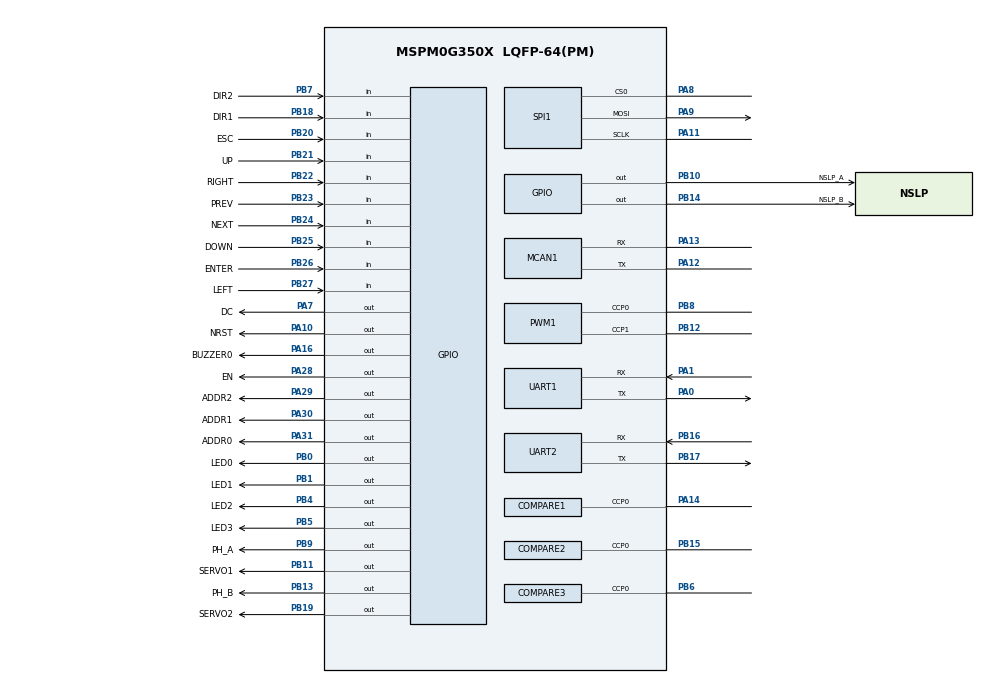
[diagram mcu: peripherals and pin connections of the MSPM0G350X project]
/**
 * @cliArgs --device "MSPM0G350X" --part "Default" --package "LQFP-64(PM)" --product "mspm0_sdk@2.05.01.00"
 * @versions {"tool":"1.24.1+4189"}
 */

/**
 * Import the modules used in this configuration.
 */
const ADC12         = scripting.addModule("/ti/driverlib/ADC12", {}, false);
const ADC121        = ADC12.addInstance();
const COMPARE       = scripting.addModule("/ti/driverlib/COMPARE", {}, false);
const COMPARE1      = COMPARE.addInstance();
const COMPARE2      = COMPARE.addInstance();
const COMPARE3      = COMPARE.addInstance();
const GPIO          = scripting.addModule("/ti/driverlib/GPIO", {}, false);
const GPIO1         = GPIO.addInstance();
const GPIO2         = GPIO.addInstance();
const GPIO3         = GPIO.addInstance();
const GPIO4         = GPIO.addInstance();
const GPIO5         = GPIO.addInstance();
const GPIO6         = GPIO.addInstance();
const GPIO7         = GPIO.addInstance();
const GPIO8         = GPIO.addInstance();
const GPIO9         = GPIO.addInstance();
const MATHACL       = scripting.addModule("/ti/driverlib/MATHACL");
const MCAN          = scripting.addModule("/ti/driverlib/MCAN", {}, false);
const MCAN1         = MCAN.addInstance();
const PWM           = scripting.addModule("/ti/driverlib/PWM", {}, false);
const PWM1          = PWM.addInstance();
const SPI           = scripting.addModule("/ti/driverlib/SPI", {}, false);
const SPI1          = SPI.addInstance();
const SYSCTL        = scripting.addModule("/ti/driverlib/SYSCTL");
const SYSTICK       = scripting.addModule("/ti/driverlib/SYSTICK");
const TIMER         = scripting.addModule("/ti/driverlib/TIMER", {}, false);
const TIMER1        = TIMER.addInstance();
const TIMER2        = TIMER.addInstance();
const UART          = scripting.addModule("/ti/driverlib/UART", {}, false);
const UART1         = UART.addInstance();
const UART2         = UART.addInstance();
const VREF          = scripting.addModule("/ti/driverlib/VREF");
const ProjectConfig = scripting.addModule("/ti/project_config/ProjectConfig");

/**
 * Write custom configuration values to the imported modules.
 */
const divider5       = system.clockTree["PLL_CLK1_DIV"];
divider5.divideValue = 4;

const divider6       = system.clockTree["PLL_CLK2X_DIV"];
divider6.divideValue = 4;

const divider7       = system.clockTree["PLL_PDIV"];
divider7.divideValue = 2;

const divider9       = system.clockTree["UDIV"];
divider9.divideValue = 2;

const gate7  = system.clockTree["MFCLKGATE"];
gate7.enable = true;

const gate8  = system.clockTree["MFPCLKGATE"];
gate8.enable = true;

const multiplier2         = system.clockTree["PLL_QDIV"];
multiplier2.multiplyValue = 10;

const mux2       = system.clockTree["CANCLKMUX"];
mux2.inputSelect = "CANCLKMUX_PLLCLK1_OUT";

const mux8       = system.clockTree["HSCLKMUX"];
mux8.inputSelect = "HSCLKMUX_SYSPLL2X";

ADC121.$name                 = "ADC12_0";
ADC121.samplingOperationMode = "sequence";
ADC121.adcMem0vref           = "VREF";
ADC121.sampClkSrc            = "DL_ADC12_CLOCK_ULPCLK";
ADC121.adcMem1chansel        = "DL_ADC12_INPUT_CHAN_1";
ADC121.adcMem1vref           = "VREF";
ADC121.adcMem2chansel        = "DL_ADC12_INPUT_CHAN_2";
ADC121.adcMem2vref           = "VREF";
ADC121.adcMem3chansel        = "DL_ADC12_INPUT_CHAN_3";
ADC121.adcMem3vref           = "VREF";
ADC121.adcMem4vref           = "VREF";
ADC121.sampleTime1           = "10us";
ADC121.enabledDMATriggers    = ["DL_ADC12_DMA_MEM11_RESULT_LOADED","DL_ADC12_DMA_MEM5_RESULT_LOADED"];
ADC121.enableDMA             = false;
ADC121.repeatMode            = true;
ADC121.endAdd                = 6;
ADC121.adcMem4chansel        = "DL_ADC12_INPUT_CHAN_7";
ADC121.adcMem5chansel        = "DL_ADC12_INPUT_CHAN_11";
ADC121.adcMem6chansel        = "DL_ADC12_INPUT_CHAN_15";
ADC121.adcMem6vref           = "VREF";
ADC121.enabledInterrupts     = ["DL_ADC12_INTERRUPT_MEM6_RESULT_LOADED"];
ADC121.adcMem5vref           = "VREF";
ADC121.sampleTime0           = "2us";
ADC121.adcMem0stime          = "DL_ADC12_SAMPLE_TIMER_SOURCE_SCOMP1";
ADC121.adcMem1stime          = "DL_ADC12_SAMPLE_TIMER_SOURCE_SCOMP1";
ADC121.adcMem2stime          = "DL_ADC12_SAMPLE_TIMER_SOURCE_SCOMP1";
ADC121.adcMem3stime          = "DL_ADC12_SAMPLE_TIMER_SOURCE_SCOMP1";
ADC121.adcMem4stime          = "DL_ADC12_SAMPLE_TIMER_SOURCE_SCOMP1";
ADC121.adcMem5stime          = "DL_ADC12_SAMPLE_TIMER_SOURCE_SCOMP1";
ADC121.adcMem6stime          = "DL_ADC12_SAMPLE_TIMER_SOURCE_SCOMP1";
ADC121.adcPin0Config.$name   = "ti_driverlib_gpio_GPIOPinGeneric11";
ADC121.adcPin1Config.$name   = "ti_driverlib_gpio_GPIOPinGeneric12";
ADC121.adcPin2Config.$name   = "ti_driverlib_gpio_GPIOPinGeneric13";
ADC121.adcPin3Config.$name   = "ti_driverlib_gpio_GPIOPinGeneric14";
ADC121.adcPin7Config.$name   = "ti_driverlib_gpio_GPIOPinGeneric19";

const Board = scripting.addModule("/ti/driverlib/Board", {}, false);

COMPARE1.$name                      = "COMPARE_0";
COMPARE1.timerPeriod                = 65535;
COMPARE1.peripheral.$assign         = "TIMG12";
COMPARE1.peripheral.ccp0Pin.$assign = "PA14";
COMPARE1.ccp0PinConfig.$name        = "CC";

COMPARE2.$name                      = "COMPARE_1";
COMPARE2.timerPeriod                = 65535;
COMPARE2.peripheral.$assign         = "TIMG7";
COMPARE2.peripheral.ccp0Pin.$assign = "PB15";
COMPARE2.ccp0PinConfig.$name        = "ti_driverlib_gpio_GPIOPinGeneric5";

COMPARE3.$name                      = "COMPARE_2";
COMPARE3.timerPeriod                = 65535;
COMPARE3.peripheral.$assign         = "TIMG6";
COMPARE3.peripheral.ccp0Pin.$assign = "PB6";
COMPARE3.ccp0PinConfig.$name        = "ti_driverlib_gpio_GPIOPinGeneric6";

GPIO1.$name                          = "LED";
GPIO1.associatedPins.create(4);
GPIO1.associatedPins[0].$name        = "LED0";
GPIO1.associatedPins[0].assignedPort = "PORTB";
GPIO1.associatedPins[0].assignedPin  = "0";
GPIO1.associatedPins[0].initialValue = "SET";
GPIO1.associatedPins[0].pin.$assign  = "PB0";
GPIO1.associatedPins[1].assignedPort = "PORTB";
GPIO1.associatedPins[1].assignedPin  = "1";
GPIO1.associatedPins[1].$name        = "LED1";
GPIO1.associatedPins[1].initialValue = "SET";
GPIO1.associatedPins[1].pin.$assign  = "PB1";
GPIO1.associatedPins[2].$name        = "LED2";
GPIO1.associatedPins[2].assignedPort = "PORTB";
GPIO1.associatedPins[2].assignedPin  = "4";
GPIO1.associatedPins[2].initialValue = "SET";
GPIO1.associatedPins[2].pin.$assign  = "PB4";
GPIO1.associatedPins[3].$name        = "LED3";
GPIO1.associatedPins[3].assignedPort = "PORTB";
GPIO1.associatedPins[3].assignedPin  = "5";
GPIO1.associatedPins[3].initialValue = "SET";
GPIO1.associatedPins[3].pin.$assign  = "PB5";

GPIO2.$name                          = "BUZZER";
GPIO2.associatedPins[0].$name        = "BUZZER0";
GPIO2.associatedPins[0].initialValue = "SET";
GPIO2.associatedPins[0].assignedPort = "PORTA";
GPIO2.associatedPins[0].assignedPin  = "16";
GPIO2.associatedPins[0].pin.$assign  = "PA16";

GPIO3.$name                         = "BUTTON";
GPIO3.port                          = "PORTB";
GPIO3.associatedPins.create(8);
GPIO3.associatedPins[0].$name       = "UP";
GPIO3.associatedPins[0].assignedPin = "21";
GPIO3.associatedPins[0].direction   = "INPUT";
GPIO3.associatedPins[0].pin.$assign = "PB21";
GPIO3.associatedPins[1].$name       = "DOWN";
GPIO3.associatedPins[1].assignedPin = "25";
GPIO3.associatedPins[1].direction   = "INPUT";
GPIO3.associatedPins[1].pin.$assign = "PB25";
GPIO3.associatedPins[2].$name       = "LEFT";
GPIO3.associatedPins[2].assignedPin = "27";
GPIO3.associatedPins[2].direction   = "INPUT";
GPIO3.associatedPins[2].pin.$assign = "PB27";
GPIO3.associatedPins[3].$name       = "RIGHT";
GPIO3.associatedPins[3].assignedPin = "22";
GPIO3.associatedPins[3].direction   = "INPUT";
GPIO3.associatedPins[3].pin.$assign = "PB22";
GPIO3.associatedPins[4].$name       = "PREV";
GPIO3.associatedPins[4].assignedPin = "23";
GPIO3.associatedPins[4].direction   = "INPUT";
GPIO3.associatedPins[4].pin.$assign = "PB23";
GPIO3.associatedPins[5].$name       = "NEXT";
GPIO3.associatedPins[5].assignedPin = "24";
GPIO3.associatedPins[5].direction   = "INPUT";
GPIO3.associatedPins[5].pin.$assign = "PB24";
GPIO3.associatedPins[6].$name       = "ENTER";
GPIO3.associatedPins[6].assignedPin = "26";
GPIO3.associatedPins[6].direction   = "INPUT";
GPIO3.associatedPins[6].pin.$assign = "PB26";
GPIO3.associatedPins[7].$name       = "ESC";
GPIO3.associatedPins[7].assignedPin = "20";
GPIO3.associatedPins[7].direction   = "INPUT";
GPIO3.associatedPins[7].pin.$assign = "PB20";

GPIO4.$name                          = "OLED";
GPIO4.associatedPins.create(2);
GPIO4.associatedPins[0].$name        = "DC";
GPIO4.associatedPins[0].assignedPort = "PORTA";
GPIO4.associatedPins[0].assignedPin  = "7";
GPIO4.associatedPins[0].pin.$assign  = "PA7";
GPIO4.associatedPins[1].$name        = "NRST";
GPIO4.associatedPins[1].assignedPort = "PORTA";
GPIO4.associatedPins[1].assignedPin  = "10";
GPIO4.associatedPins[1].pin.$assign  = "PA10";

GPIO5.$name                       = "ENCODERA";
GPIO5.port                        = "PORTA";
GPIO5.associatedPins[0].direction = "INPUT";
GPIO5.associatedPins[0].$name     = "DIR0";

GPIO6.$name                         = "ENCODERB";
GPIO6.associatedPins.create(2);
GPIO6.associatedPins[0].direction   = "INPUT";
GPIO6.associatedPins[0].$name       = "DIR1";
GPIO6.associatedPins[0].pin.$assign = "PB18";
GPIO6.associatedPins[1].direction   = "INPUT";
GPIO6.associatedPins[1].$name       = "DIR2";
GPIO6.associatedPins[1].pin.$assign = "PB7";

GPIO7.$name                         = "MOTOR";
GPIO7.port                          = "PORTB";
GPIO7.associatedPins.create(4);
GPIO7.associatedPins[0].$name       = "NSLP_A";
GPIO7.associatedPins[0].pin.$assign = "PB10";
GPIO7.associatedPins[1].$name       = "PH_A";
GPIO7.associatedPins[1].pin.$assign = "PB9";
GPIO7.associatedPins[2].$name       = "NSLP_B";
GPIO7.associatedPins[2].pin.$assign = "PB14";
GPIO7.associatedPins[3].$name       = "PH_B";
GPIO7.associatedPins[3].pin.$assign = "PB13";

GPIO8.$name                         = "SERVO";
GPIO8.associatedPins.create(2);
GPIO8.associatedPins[0].$name       = "SERVO1";
GPIO8.associatedPins[0].pin.$assign = "PB11";
GPIO8.associatedPins[1].$name       = "SERVO2";
GPIO8.associatedPins[1].pin.$assign = "PB19";

GPIO9.$name                          = "OEMT";
GPIO9.associatedPins.create(4);
GPIO9.associatedPins[0].$name        = "EN";
GPIO9.associatedPins[0].assignedPort = "PORTA";
GPIO9.associatedPins[0].assignedPin  = "28";
GPIO9.associatedPins[0].pin.$assign  = "PA28";
GPIO9.associatedPins[1].$name        = "ADDR0";
GPIO9.associatedPins[1].assignedPort = "PORTA";
GPIO9.associatedPins[1].assignedPin  = "31";
GPIO9.associatedPins[1].pin.$assign  = "PA31";
GPIO9.associatedPins[2].$name        = "ADDR1";
GPIO9.associatedPins[2].assignedPort = "PORTA";
GPIO9.associatedPins[2].assignedPin  = "30";
GPIO9.associatedPins[2].pin.$assign  = "PA30";
GPIO9.associatedPins[3].assignedPort = "PORTA";
GPIO9.associatedPins[3].assignedPin  = "29";
GPIO9.associatedPins[3].$name        = "ADDR2";
GPIO9.associatedPins[3].pin.$assign  = "PA29";

MCAN1.$name                    = "MCAN0";
MCAN1.fdMode                   = false;
MCAN1.wkupReqEnable            = true;
MCAN1.autoWkupEnable           = true;
MCAN1.emulationEnable          = true;
MCAN1.enableInterrupt          = true;
MCAN1.desiredDataRate          = 0.5;
MCAN1.txBufElemSize            = "DL_MCAN_ELEM_SIZE_8BYTES";
MCAN1.interruptFlags           = ["DL_MCAN_INTERRUPT_RF0F","DL_MCAN_INTERRUPT_RF0N"];
MCAN1.interruptLine            = ["DL_MCAN_INTR_LINE_NUM_1"];
MCAN1.m0interrupts             = ["DL_MCAN_MSP_INTERRUPT_LINE1"];
MCAN1.interruptLine1Flag       = ["DL_MCAN_INTERRUPT_RF0F","DL_MCAN_INTERRUPT_RF0N"];
MCAN1.peripheral.rxPin.$assign = "PA13";
MCAN1.peripheral.txPin.$assign = "PA12";
MCAN1.txPinConfig.$name        = "ti_driverlib_gpio_GPIOPinGeneric2";
MCAN1.rxPinConfig.$name        = "ti_driverlib_gpio_GPIOPinGeneric4";

PWM1.$name                      = "PWM_0";
PWM1.clockPrescale              = 5;
PWM1.enableShadowLoad           = true;
PWM1.pwmMode                    = "EDGE_ALIGN_UP";
PWM1.peripheral.ccp0Pin.$assign = "PB8";
PWM1.peripheral.ccp1Pin.$assign = "PB12";
PWM1.PWM_CHANNEL_0.$name        = "ti_driverlib_pwm_PWMTimerCC0";
PWM1.PWM_CHANNEL_1.$name        = "ti_driverlib_pwm_PWMTimerCC1";
PWM1.ccp0PinConfig.$name        = "ti_driverlib_gpio_GPIOPinGeneric7";
PWM1.ccp1PinConfig.$name        = "ti_driverlib_gpio_GPIOPinGeneric8";

SPI1.direction                          = "PICO";
SPI1.$name                              = "SPI_1";
SPI1.rxFifoThreshold                    = "DL_SPI_RX_FIFO_LEVEL_ONE_FRAME";
SPI1.enabledDMAEvent2Triggers           = "DL_SPI_DMA_INTERRUPT_TX";
SPI1.txFifoThreshold                    = "DL_SPI_TX_FIFO_LEVEL_ONE_FRAME";
SPI1.targetBitRate                      = 800000;
SPI1.enabledInterrupts                  = ["DMA_DONE_TX"];
SPI1.sclkPinConfig.direction            = scripting.forceWrite("OUTPUT");
SPI1.sclkPinConfig.onlyInternalResistor = scripting.forceWrite(false);
SPI1.sclkPinConfig.passedPeripheralType = scripting.forceWrite("Digital");
SPI1.sclkPinConfig.$name                = "ti_driverlib_gpio_GPIOPinGeneric0";
SPI1.mosiPinConfig.direction            = scripting.forceWrite("OUTPUT");
SPI1.mosiPinConfig.hideOutputInversion  = scripting.forceWrite(false);
SPI1.mosiPinConfig.onlyInternalResistor = scripting.forceWrite(false);
SPI1.mosiPinConfig.passedPeripheralType = scripting.forceWrite("Digital");
SPI1.mosiPinConfig.$name                = "ti_driverlib_gpio_GPIOPinGeneric1";
SPI1.cs0PinConfig.direction             = scripting.forceWrite("OUTPUT");
SPI1.cs0PinConfig.hideOutputInversion   = scripting.forceWrite(false);
SPI1.cs0PinConfig.onlyInternalResistor  = scripting.forceWrite(false);
SPI1.cs0PinConfig.passedPeripheralType  = scripting.forceWrite("Digital");
SPI1.cs0PinConfig.$name                 = "ti_driverlib_gpio_GPIOPinGeneric3";
SPI1.peripheral.$assign                 = "SPI0";
SPI1.peripheral.sclkPin.$assign         = "PA11";
SPI1.peripheral.mosiPin.$assign         = "PA9";
SPI1.peripheral.cs0Pin.$assign          = "PA8";
SPI1.DMA_CHANNEL_EVENT2.addressMode     = "b2f";
SPI1.DMA_CHANNEL_EVENT2.srcLength       = "BYTE";
SPI1.DMA_CHANNEL_EVENT2.dstLength       = "BYTE";
SPI1.DMA_CHANNEL_EVENT2.transferSize    = 8;
SPI1.DMA_CHANNEL_EVENT2.enableInterrupt = true;
SPI1.DMA_CHANNEL_EVENT2.$name           = "DMA_CH_SPI0_TX";

SYSCTL.clockTreeEn = true;

SYSTICK.periodEnable    = true;
SYSTICK.interruptEnable = true;
SYSTICK.period          = 80000;
SYSTICK.systickEnable   = true;

TIMER1.interrupts       = ["LOAD"];
TIMER1.$name            = "TIMER_OEMT";
TIMER1.timerMode        = "PERIODIC";
TIMER1.timerClkPrescale = 40;
TIMER1.timerPeriod      = "125us";

TIMER2.$name = "TIMER_SREVO";

UART1.$name                        = "UART_0";
UART1.txFifoThreshold              = "DL_UART_TX_FIFO_LEVEL_1_4_EMPTY";
UART1.targetBaudRate               = 115200;
UART1.enabledInterrupts            = ["DMA_DONE_RX","DMA_DONE_TX","RX","TX"];
UART1.enabledDMARXTriggers         = "DL_UART_DMA_INTERRUPT_RX";
UART1.enabledDMATXTriggers         = "DL_UART_DMA_INTERRUPT_TX";
UART1.peripheral.$assign           = "UART0";
UART1.peripheral.rxPin.$assign     = "PA1";
UART1.peripheral.txPin.$assign     = "PA0";
UART1.txPinConfig.$name            = "ti_driverlib_gpio_GPIOPinGeneric9";
UART1.txPinConfig.internalResistor = "PULL_UP";
UART1.rxPinConfig.$name            = "ti_driverlib_gpio_GPIOPinGeneric10";
UART1.DMA_CHANNEL_RX.srcLength     = "BYTE";
UART1.DMA_CHANNEL_RX.dstLength     = "BYTE";
UART1.DMA_CHANNEL_RX.addressMode   = "f2b";
UART1.DMA_CHANNEL_RX.$name         = "DMA_CH_UART0_RX";
UART1.DMA_CHANNEL_TX.addressMode   = "b2f";
UART1.DMA_CHANNEL_TX.srcLength     = "BYTE";
UART1.DMA_CHANNEL_TX.dstLength     = "BYTE";
UART1.DMA_CHANNEL_TX.$name         = "DMA_CH_UART0_TX";

UART2.$name                      = "UART_1";
UART2.targetBaudRate             = 115200;
UART2.enabledInterrupts          = ["DMA_DONE_RX","DMA_DONE_TX","RX","TX"];
UART2.enabledDMARXTriggers       = "DL_UART_DMA_INTERRUPT_RX";
UART2.enabledDMATXTriggers       = "DL_UART_DMA_INTERRUPT_TX";
UART2.peripheral.rxPin.$assign   = "PB16";
UART2.peripheral.txPin.$assign   = "PB17";
UART2.txPinConfig.$name          = "ti_driverlib_gpio_GPIOPinGeneric17";
UART2.rxPinConfig.$name          = "ti_driverlib_gpio_GPIOPinGeneric18";
UART2.DMA_CHANNEL_RX.$name       = "DMA_CH0";
UART2.DMA_CHANNEL_RX.srcLength   = "BYTE";
UART2.DMA_CHANNEL_RX.dstLength   = "BYTE";
UART2.DMA_CHANNEL_RX.addressMode = "f2b";
UART2.DMA_CHANNEL_TX.$name       = "DMA_CH1";
UART2.DMA_CHANNEL_TX.srcLength   = "BYTE";
UART2.DMA_CHANNEL_TX.dstLength   = "BYTE";
UART2.DMA_CHANNEL_TX.addressMode = "b2f";

VREF.basicMode              = "DL_VREF_ENABLE_DISABLE";
VREF.basicExtVolt           = 3.3;
VREF.basicVrefPins          = "VREF+-";
VREF.vrefPosPinConfig.$name = "ti_driverlib_gpio_GPIOPinGeneric15";
VREF.vrefNegPinConfig.$name = "ti_driverlib_gpio_GPIOPinGeneric16";

ProjectConfig.genLibCMSIS = true;

/**
 * Pinmux solution for unlocked pins/peripherals. This ensures that minor changes to the automatic solver in a future
 * version of the tool will not impact the pinmux you originally saw.  These lines can be completely deleted in order to
 * re-solve from scratch.
 */
ADC121.peripheral.$suggestSolution                  = "ADC0";
ADC121.peripheral.adcPin0.$suggestSolution          = "PA27";
ADC121.peripheral.adcPin1.$suggestSolution          = "PA26";
ADC121.peripheral.adcPin2.$suggestSolution          = "PA25";
ADC121.peripheral.adcPin3.$suggestSolution          = "PA24";
ADC121.peripheral.adcPin7.$suggestSolution          = "PA22";
Board.peripheral.$suggestSolution                   = "DEBUGSS";
Board.peripheral.swclkPin.$suggestSolution          = "PA20";
Board.peripheral.swdioPin.$suggestSolution          = "PA19";
GPIO5.associatedPins[0].pin.$suggestSolution        = "PA15";
MCAN1.peripheral.$suggestSolution                   = "CANFD0";
PWM1.peripheral.$suggestSolution                    = "TIMA0";
SPI1.DMA_CHANNEL_EVENT2.peripheral.$suggestSolution = "DMA_CH4";
TIMER1.peripheral.$suggestSolution                  = "TIMG0";
TIMER2.peripheral.$suggestSolution                  = "TIMA1";
UART1.DMA_CHANNEL_RX.peripheral.$suggestSolution    = "DMA_CH3";
UART1.DMA_CHANNEL_TX.peripheral.$suggestSolution    = "DMA_CH2";
UART2.peripheral.$suggestSolution                   = "UART2";
UART2.DMA_CHANNEL_RX.peripheral.$suggestSolution    = "DMA_CH1";
UART2.DMA_CHANNEL_TX.peripheral.$suggestSolution    = "DMA_CH0";
VREF.peripheral.$suggestSolution                    = "VREF";
VREF.peripheral.vrefPosPin.$suggestSolution         = "PA23";
VREF.peripheral.vrefNegPin.$suggestSolution         = "PA21";
